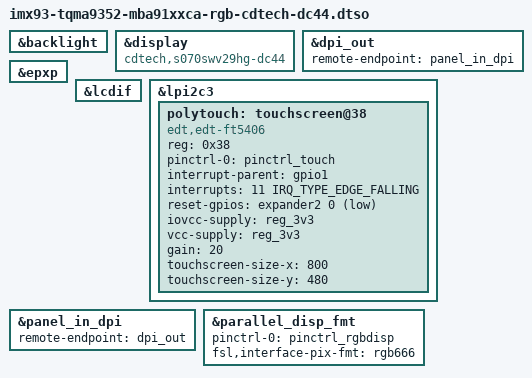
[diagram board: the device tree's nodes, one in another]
// SPDX-License-Identifier: (GPL-2.0-or-later OR MIT)
/*
 * Copyright (c) 2023-2024 TQ-Systems GmbH <linux@ew.tq-group.com>,
 * D-82229 Seefeld, Germany.
 * Author: Alexander Stein
 */

#include <dt-bindings/gpio/gpio.h>
#include <dt-bindings/interrupt-controller/irq.h>

/dts-v1/;
/plugin/;

&backlight {
	status = "okay";
};

&display {
	compatible = "cdtech,s070swv29hg-dc44";
	status = "okay";
};

&dpi_out {
	remote-endpoint = <&panel_in_dpi>;
};

&epxp {
	status = "okay";
};

&lcdif {
	status = "okay";
};

&lpi2c3 {
	polytouch: touchscreen@38 {
		compatible = "edt,edt-ft5406";
		reg = <0x38>;
		pinctrl-names = "default";
		pinctrl-0 = <&pinctrl_touch>;
		interrupt-parent = <&gpio1>;
		interrupts = <11 IRQ_TYPE_EDGE_FALLING>;
		reset-gpios = <&expander2 0 GPIO_ACTIVE_LOW>;
		iovcc-supply = <&reg_3v3>;
		vcc-supply = <&reg_3v3>;
		gain = <20>;
		touchscreen-size-x = <800>;
		touchscreen-size-y = <480>;
	};
};

&panel_in_dpi {
	remote-endpoint = <&dpi_out>;
};

&parallel_disp_fmt {
	pinctrl-names = "default";
	pinctrl-0 = <&pinctrl_rgbdisp>;
	fsl,interface-pix-fmt = "rgb666";
	status = "okay";
};
